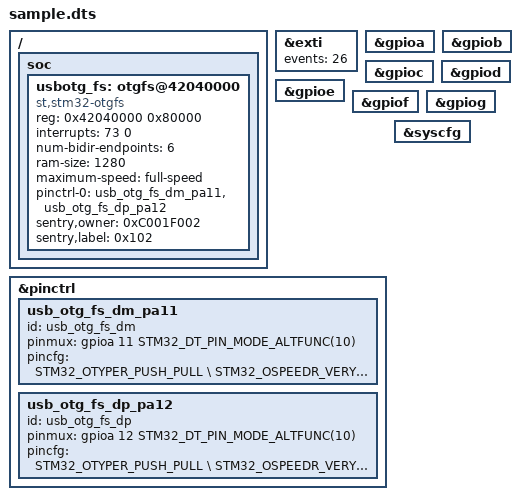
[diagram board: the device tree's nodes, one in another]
// SPDX-License-Identifier: Apache-2.0
// Copyright (c) 2026 H2Lab Development Team

/dts-v1/;

#include <st/u5/stm32u599.dtsi>
#include <dt-bindings/pinctrl/stm32-pinctrl.h>
#include <sentry.dtsi>

/{
	soc {
		usbotg_fs: otgfs@42040000 {
			compatible = "st,stm32-otgfs";
			reg = <0x42040000 0x80000>;
			interrupts = <73 0>;
			interrupt-names = "otgfs";
			num-bidir-endpoints = <6>;
			ram-size = <1280>;
			maximum-speed = "full-speed";
			pinctrl-names = "default";
			pinctrl-0 = <&usb_otg_fs_dm_pa11>, <&usb_otg_fs_dp_pa12>;
			sentry,owner = <0xC001F002>;
			sentry,label = <0x102>;
			status = "okay";
		};
	};
};
&exti {
	events = <26>;
	status = "okay";
};

&gpioa {
	status = "okay";
};

&gpiob {
	status = "okay";
};

&gpioc {
	status = "okay";
};

&gpiod {
	status = "okay";
};

&gpioe {
	status = "okay";
};

&gpiof {
	status = "okay";
};

&gpiog {
	status = "okay";
};



&pinctrl {
	usb_otg_fs_dm_pa11: usb_otg_fs_dm_pa11 {
		id = "usb_otg_fs_dm";
		pinmux = <&gpioa 11 STM32_DT_PIN_MODE_ALTFUNC(10)>;
		pincfg = <STM32_OTYPER_PUSH_PULL \
			  STM32_OSPEEDR_VERY_HIGH_SPEED \
			  STM32_PUPDR_NO_PULL>;
	};

	usb_otg_fs_dp_pa12: usb_otg_fs_dp_pa12 {
		id = "usb_otg_fs_dp";
		pinmux = <&gpioa 12 STM32_DT_PIN_MODE_ALTFUNC(10)>;
		pincfg = <STM32_OTYPER_PUSH_PULL \
			  STM32_OSPEEDR_VERY_HIGH_SPEED \
			  STM32_PUPDR_NO_PULL>;
	};

};

&syscfg {
	status = "okay";
};
